# QN908XC register map
Vendor: nxp.com; File version: 1.0
CPU: CM4 r0p1, little endian, no MPU, no FPU, 0x3 interrupt priority bits, 0x0 interrupts
Registers are 32-bit, read-write, reset 0x0 unless marked. A register's access mark holds for its fields unless they carry their own. Offsets are from the block's base; [hi:lo] are bit positions.

## RNG
Base 0x40007C00
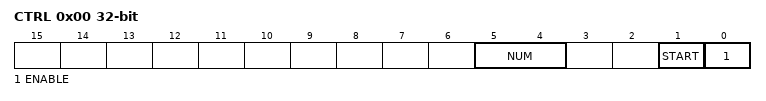
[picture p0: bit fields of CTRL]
0x00 CTRL (reset mask 0x31) — control register
  [5:4] NUM — total bits
  [1] START wo — write 1 to start random number generation, auto clear
  [0] ENABLE — write 1 to enable randome number generator
0x04 STAT ro — status register
  [0] BUSY — module in processing
0x08 DATA ro — random data output register
  [31:0] DATA — final random data read by SW
0x0C INT — interrupt register
  [0] DONE write-1-clears — random data generate done
0x10 INTEN — interrupt mask register
  [0] DONE_INTEN — random data generate done mask

## QDEC0 — qdec
Base 0x40009000
Same registers: QDEC1 0x40009800
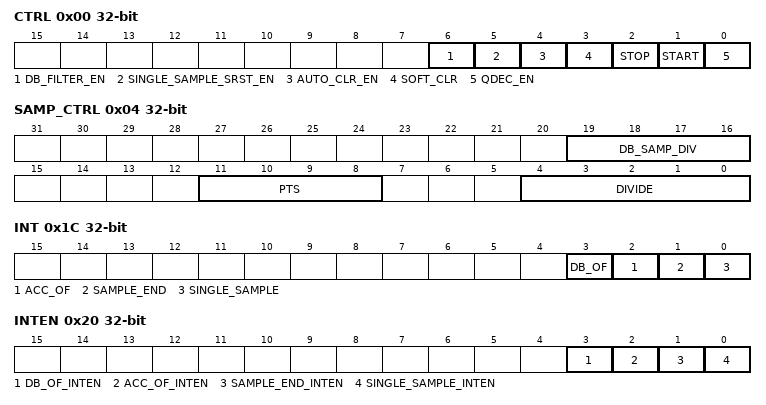
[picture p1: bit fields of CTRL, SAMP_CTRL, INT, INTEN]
0x00 CTRL (reset mask 0x71) — control register
  [6] DB_FILTER_EN, [5] SINGLE_SAMPLE_SRST_EN, [4] AUTO_CLR_EN, [3] SOFT_CLR wo, [2] STOP wo, [1] START wo, [0] QDEC_EN
0x04 SAMP_CTRL — QDEC sample settting register
  [19:16] DB_SAMP_DIV — Debounce filter sample clk devide cf. 8.3
  [11:8] PTS — total sample points 0~11 total 12modes cf. 8.2
    0=5 points; 1=10 points; 2=40 points; 3=80 points; 4=120 points; 5=160 points; 6=200 points; 7=240 points; 8=280 points; 9=320 points; 10=360 points; 11=400 points
  [4:0] DIVIDE — divide number to APB clk 0~20 total 21modes
0x08 SAMPLE ro — QDEC sample result register
  [1:0] SAMPLE — Sample value each time (2's complement)
0x0C ACC ro — QDEC accumulate register
  [10:0] ACC — shift counter (-1 & +1 ) normal case
0x10 ACC_R ro — QDEC accumulate snapshot register
  [10:0] ACC_R — ACC RO snapshot when END event is valid
0x14 DB ro — double sample register
  [3:0] DB — 2 trans counter ERROR case max value 15.
0x18 DB_R ro — DB snapshot register
  [3:0] DB_R — DB_R RO snapshot when END event is valid
0x1C INT — interrupt register
  [3] DB_OF write-1-clears — Double sample (2 trans )number is overflow
  [2] ACC_OF write-1-clears — Normal sample (+1/-1) number is overflow
  [1] SAMPLE_END write-1-clears — END event triggered
  [0] SINGLE_SAMPLE write-1-clears — Each time when normal sample is done
0x20 INTEN — interrupt mask register
  [3] DB_OF_INTEN — double sample overflow interrupt enable
  [2] ACC_OF_INTEN — normal sample overflow interrupt enable
  [1] SAMPLE_END_INTEN — sample end interrupt enable
  [0] SINGLE_SAMPLE_INTEN — single sample done interrupt enable
0x24 STAT ro — QDEC is running
  [0] BUSY

## RTC
Base 0x4000B000
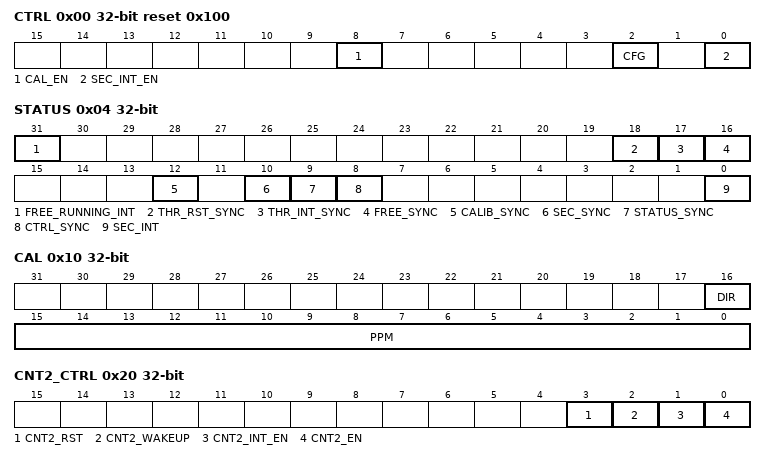
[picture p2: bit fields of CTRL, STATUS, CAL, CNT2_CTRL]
0x00 CTRL reset 0x100 — RTC control register
  [8] CAL_EN — Calibration enable
  [2] CFG — RTC second configuration control. This bit is self-cleared after synchronization
  [0] SEC_INT_EN — RTC second interrupt enable
0x04 STATUS — RTC status register
  [31] FREE_RUNNING_INT ro — Free running interrupt status.
  [18] THR_RST_SYNC ro — Free running counter Reset Threshold Register synchronization busy indicator
  [17] THR_INT_SYNC ro — Free running counter interrupt Threshold Register synchronization busy indicator
  [16] FREE_SYNC ro — Free running counter control Register synchronization busy indicator
  [12] CALIB_SYNC ro — Calibration Register synchronization busy indicator
  [10] SEC_SYNC ro — Second configuration Register synchronization busy indicator
  [9] STATUS_SYNC ro — Status Register synchronization busy indicator
  [8] CTRL_SYNC ro — Control Register synchronization busy indicator
  [0] SEC_INT write-1-clears — Second interrupt flag
0x08 SEC — RTC second register
  [31:0] SEC — Second configuration register.
0x10 CAL — RTC calibration register
  [16] DIR — RTC calibration direction indicator
    0=FORWARD (forward calibrate); 1=BACKWARD (backward calibrate)
  [15:0] PPM — RTC calibration ppm value the precision is 1 ppm.
0x14 CNT_VAL ro — RTC count value register
  [14:0] CNT — RTC counter current value read only.
0x20 CNT2_CTRL — Free running control register
  [3] CNT2_RST — 1 to enable free running reset
  [2] CNT2_WAKEUP — 1 to enable free running wakeup
  [1] CNT2_INT_EN — 1 to enable free running interrupt
  [0] CNT2_EN — 1 to enable free running counter
0x24 THR_INT reset 0xF000000 — interrupt threshold of free running counter register
  [31:0] THR_INT — The Threshold of free running counter is to generate free running interrupt.
0x28 THR_RST reset 0xFF000000 — reset threshold of free running counter register
  [31:0] THR_RST — The Threshold of free running counter is to generate free running reset.
0x2C CNT2 ro — free running count value
  [31:0] CNT2 — The current value of free running counter
